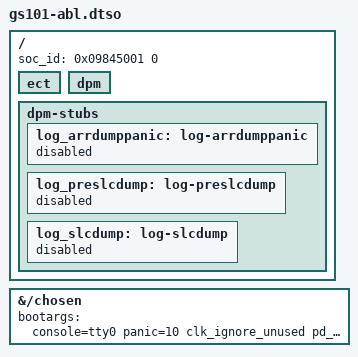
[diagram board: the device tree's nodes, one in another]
// SPDX-License-Identifier: GPL-2.0-only
/* ABL metadata only; retain all hardware nodes from the pinned GS101 tree. */
/dts-v1/;
/plugin/;

/ {
	fragment@0 {
		target-path = "/";
		__overlay__ {
			soc_id = <0x09845001 0>;
			ect {};
			dpm: dpm {};
			dpm-stubs {
				log_arrdumppanic: log-arrdumppanic { status = "disabled"; };
				log_preslcdump: log-preslcdump { status = "disabled"; };
				log_slcdump: log-slcdump { status = "disabled"; };
			};
		};
	};

	fragment@1 {
		target-path = "/chosen";
		__overlay__ {
			bootargs = "console=tty0 panic=10 clk_ignore_unused pd_ignore_unused rdinit=/init omamobile.initramfs";
		};
	};
};
